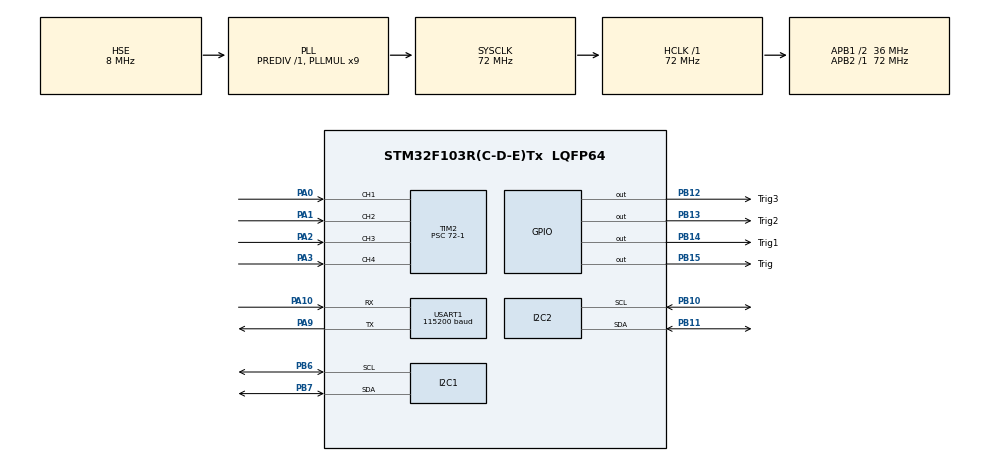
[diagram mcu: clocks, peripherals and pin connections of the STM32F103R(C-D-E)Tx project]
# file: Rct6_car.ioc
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FREERTOS.Tasks01=defaultTask,24,128,StartDefaultTask,Default,NULL,Dynamic,NULL,NULL;myTask02,8,128,StartTask02,Default,NULL,Dynamic,NULL,NULL;myTask03,9,128,StartTask03,Default,NULL,Dynamic,NULL,NULL
I2C1.I2C_Mode=I2C_Fast
I2C2.I2C_Mode=I2C_Fast
Mcu.Family=STM32F1
Mcu.Name=STM32F103R(C-D-E)Tx
Mcu.Package=LQFP64
NVIC.PriorityGroup=NVIC_PRIORITYGROUP_4
NVIC.TIM2_IRQn=true\:5\:0\:true\:false\:true\:true\:true\:true\:true
NVIC.TIM7_IRQn=true\:5\:0\:false\:false\:true\:true\:true\:true\:true
NVIC.TIM8_UP_IRQn=true\:15\:0\:false\:false\:true\:false\:false\:true\:true
NVIC.TimeBase=TIM8_UP_IRQn
NVIC.TimeBaseIP=TIM8
PA0-WKUP.Signal=S_TIM2_CH1_ETR
PA1.Signal=S_TIM2_CH2
PA10.Mode=Asynchronous
PA10.Signal=USART1_RX
PA13.Mode=Serial_Wire
PA13.Signal=SYS_JTMS-SWDIO
PA14.Mode=Serial_Wire
PA14.Signal=SYS_JTCK-SWCLK
PA2.Signal=S_TIM2_CH3
PA3.Signal=S_TIM2_CH4
PA9.Mode=Asynchronous
PA9.Signal=USART1_TX
PB10.Mode=I2C
PB10.Signal=I2C2_SCL
PB11.Mode=I2C
PB11.Signal=I2C2_SDA
PB12.GPIO_Label=Trig3
PB12.Signal=GPIO_Output
PB13.GPIO_Label=Trig2
PB13.Signal=GPIO_Output
PB14.GPIO_Label=Trig1
PB14.Signal=GPIO_Output
PB15.GPIO_Label=Trig
PB15.Signal=GPIO_Output
PB6.Mode=I2C
PB6.Signal=I2C1_SCL
PB7.Mode=I2C
PB7.Signal=I2C1_SDA
PD0-OSC_IN.Mode=HSE-External-Oscillator
PD0-OSC_IN.Signal=RCC_OSC_IN
PD1-OSC_OUT.Mode=HSE-External-Oscillator
PD1-OSC_OUT.Signal=RCC_OSC_OUT
ProjectManager.HeapSize=0x200
ProjectManager.StackSize=0x400
ProjectManager.TargetToolchain=MDK-ARM V5.32
RCC.AHBFreq_Value=72000000
RCC.APB1CLKDivider=RCC_HCLK_DIV2
RCC.APB1Freq_Value=36000000
RCC.APB1TimFreq_Value=72000000
RCC.APB2Freq_Value=72000000
RCC.APB2TimFreq_Value=72000000
RCC.HCLKFreq_Value=72000000
RCC.PLLMUL=RCC_PLL_MUL9
RCC.PLLSourceVirtual=RCC_PLLSOURCE_HSE
RCC.SYSCLKFreq_VALUE=72000000
RCC.SYSCLKSource=RCC_SYSCLKSOURCE_PLLCLK
RCC.USBFreq_Value=72000000
SH.S_TIM2_CH1_ETR.0=TIM2_CH1,Input_Capture1_from_TI1
SH.S_TIM2_CH2.0=TIM2_CH2,Input_Capture2_from_TI2
SH.S_TIM2_CH3.0=TIM2_CH3,Input_Capture3_from_TI3
SH.S_TIM2_CH4.0=TIM2_CH4,Input_Capture4_from_TI4
TIM2.AutoReloadPreload=TIM_AUTORELOAD_PRELOAD_ENABLE
TIM2.Channel-Input_Capture1_from_TI1=TIM_CHANNEL_1
TIM2.Channel-Input_Capture2_from_TI2=TIM_CHANNEL_2
TIM2.Channel-Input_Capture3_from_TI3=TIM_CHANNEL_3
TIM2.Channel-Input_Capture4_from_TI4=TIM_CHANNEL_4
TIM2.ICFilter_CH1=5
TIM2.ICFilter_CH2=5
TIM2.ICFilter_CH3=5
TIM2.ICFilter_CH4=4
TIM2.Prescaler=72-1
TIM7.Period=100-1
TIM7.Prescaler=7200-1
USART1.BaudRate=115200
USART1.VirtualMode=VM_ASYNC
VP_FREERTOS_VS_CMSIS_V2.Mode=CMSIS_V2
VP_SYS_VS_tim8.Mode=TIM8
VP_TIM2_VS_ClockSourceINT.Mode=Internal
VP_TIM7_VS_ClockSourceINT.Mode=Enable_Timer
board=custom

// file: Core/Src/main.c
/* USER CODE BEGIN Header */
/**
  ******************************************************************************
  * @file           : main.c
  * @brief          : Main program body
  ******************************************************************************
  * @attention
  *
  * Copyright (c) 2025 STMicroelectronics.
  * All rights reserved.
  *
  * This software is licensed under terms that can be found in the LICENSE file
  * in the root directory of this software component.
  * If no LICENSE file comes with this software, it is provided AS-IS.
  *
  ******************************************************************************
  */
/* USER CODE END Header */
#include "main.h"
#include "cmsis_os.h"
#include "i2c.h"
#include "tim.h"
#include "usart.h"
#include "gpio.h"

/* USER CODE BEGIN Includes */
#include "headfile.h"
/* USER CODE END Includes */

void SystemClock_Config(void);
void MX_FREERTOS_Init(void);

int main(void)
{

  /* MCU Configuration--------------------------------------------------------*/

  /* Reset of all peripherals, Initializes the Flash interface and the Systick. */
  HAL_Init();

  /* Configure the system clock */
  SystemClock_Config();

  /* Initialize all configured peripherals */
  MX_GPIO_Init();
  MX_I2C1_Init();
  MX_I2C2_Init();
  MX_TIM7_Init();
  MX_USART1_UART_Init();
  MX_TIM2_Init();
  /* USER CODE BEGIN 2 */
//    HAL_Delay(50);
//     OLED_Init();
//    OLEDINIT();
    // �����״ν��գ����ֽ�ģʽ��
mpu9250_Start();
HAL_TIM_Base_Start_IT(&htim7);
  /* USER CODE END 2 */

  /* Init scheduler */
  osKernelInitialize();

  /* Call init function for freertos objects (in cmsis_os2.c) */
  MX_FREERTOS_Init();

  /* Start scheduler */
  osKernelStart();

  /* We should never get here as control is now taken by the scheduler */

  /* Infinite loop */
  while (1)
  {

  }
}

void SystemClock_Config(void)
{
  RCC_OscInitTypeDef RCC_OscInitStruct = {0};
  RCC_ClkInitTypeDef RCC_ClkInitStruct = {0};

  /** Initializes the RCC Oscillators according to the specified parameters
  * in the RCC_OscInitTypeDef structure.
  */
  RCC_OscInitStruct.OscillatorType = RCC_OSCILLATORTYPE_HSE;
  RCC_OscInitStruct.HSEState = RCC_HSE_ON;
  RCC_OscInitStruct.HSEPredivValue = RCC_HSE_PREDIV_DIV1;
  RCC_OscInitStruct.HSIState = RCC_HSI_ON;
  RCC_OscInitStruct.PLL.PLLState = RCC_PLL_ON;
  RCC_OscInitStruct.PLL.PLLSource = RCC_PLLSOURCE_HSE;
  RCC_OscInitStruct.PLL.PLLMUL = RCC_PLL_MUL9;
  if (HAL_RCC_OscConfig(&RCC_OscInitStruct) != HAL_OK)
  {
    Error_Handler();
  }

  /** Initializes the CPU, AHB and APB buses clocks
  */
  RCC_ClkInitStruct.ClockType = RCC_CLOCKTYPE_HCLK|RCC_CLOCKTYPE_SYSCLK
                              |RCC_CLOCKTYPE_PCLK1|RCC_CLOCKTYPE_PCLK2;
  RCC_ClkInitStruct.SYSCLKSource = RCC_SYSCLKSOURCE_PLLCLK;
  RCC_ClkInitStruct.AHBCLKDivider = RCC_SYSCLK_DIV1;
  RCC_ClkInitStruct.APB1CLKDivider = RCC_HCLK_DIV2;
  RCC_ClkInitStruct.APB2CLKDivider = RCC_HCLK_DIV1;

  if (HAL_RCC_ClockConfig(&RCC_ClkInitStruct, FLASH_LATENCY_2) != HAL_OK)
  {
    Error_Handler();
  }
}

void HAL_TIM_PeriodElapsedCallback(TIM_HandleTypeDef *htim)
{
  /* USER CODE BEGIN Callback 0 */
  if (htim->Instance == TIM7)
  {
    mpu9250go();
//      motor_scan_non_blocking();

  }
  /* USER CODE END Callback 0 */
  if (htim->Instance == TIM8)
  {
    HAL_IncTick();
  }
}

void Error_Handler(void)
{
  __disable_irq();
  while (1)
  {
  }
}

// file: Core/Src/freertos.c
/* USER CODE BEGIN Header */
/**
  ******************************************************************************
  * File Name          : freertos.c
  * Description        : Code for freertos applications
  ******************************************************************************
  * @attention
  *
  * Copyright (c) 2025 STMicroelectronics.
  * All rights reserved.
  *
  * This software is licensed under terms that can be found in the LICENSE file
  * in the root directory of this software component.
  * If no LICENSE file comes with this software, it is provided AS-IS.
  *
  ******************************************************************************
  */
/* USER CODE END Header */

#include "FreeRTOS.h"
#include "task.h"
#include "main.h"
#include "cmsis_os.h"

/* USER CODE BEGIN Includes */
#include "headfile.h"
/* USER CODE END Includes */

/* Definitions for defaultTask */
osThreadId_t defaultTaskHandle;
const osThreadAttr_t defaultTask_attributes = {
  .name = "defaultTask",
  .stack_size = 128 * 4,
  .priority = (osPriority_t) osPriorityNormal,
};
/* Definitions for myTask02 */
osThreadId_t myTask02Handle;
const osThreadAttr_t myTask02_attributes = {
  .name = "myTask02",
  .stack_size = 128 * 4,
  .priority = (osPriority_t) osPriorityLow,
};
/* Definitions for myTask03 */
osThreadId_t myTask03Handle;
const osThreadAttr_t myTask03_attributes = {
  .name = "myTask03",
  .stack_size = 128 * 4,
  .priority = (osPriority_t) osPriorityLow1,
};

void StartDefaultTask(void *argument);
void StartTask02(void *argument);
void StartTask03(void *argument);

void MX_FREERTOS_Init(void); /* (MISRA C 2004 rule 8.1) */

void MX_FREERTOS_Init(void) {

  /* Create the thread(s) */
  /* creation of defaultTask */
  defaultTaskHandle = osThreadNew(StartDefaultTask, NULL, &defaultTask_attributes);

  /* creation of myTask02 */
  myTask02Handle = osThreadNew(StartTask02, NULL, &myTask02_attributes);

  /* creation of myTask03 */
  myTask03Handle = osThreadNew(StartTask03, NULL, &myTask03_attributes);

}

void StartDefaultTask(void *argument)
{
  /* USER CODE BEGIN StartDefaultTask */
  /* Infinite loop */
   uint8_t i = 0;
  for(;;)
  {
//          motor_scan_non_blocking();
//      if(i >= 20)
//      {
//          printf("66666");
//          i = 0;
//      }
//      else
//      {
//          i++;
//      }
//
//        if (coordinate_ready) {
//            ParseCoordinate();  // ��������
//        }
    osDelay(1);
  }
  /* USER CODE END StartDefaultTask */
}

void StartTask02(void *argument)
{
  /* USER CODE BEGIN StartTask02 */
  /* Infinite loop */
  for(;;)
  {
   //mpu9250go();
    osDelay(10);
  }
  /* USER CODE END StartTask02 */
}

void StartTask03(void *argument)
{
  /* USER CODE BEGIN StartTask03 */
  /* Infinite loop */
  for(;;)
  {
//    motor_scan_non_blocking();
    osDelay(1);
  }
  /* USER CODE END StartTask03 */
}
